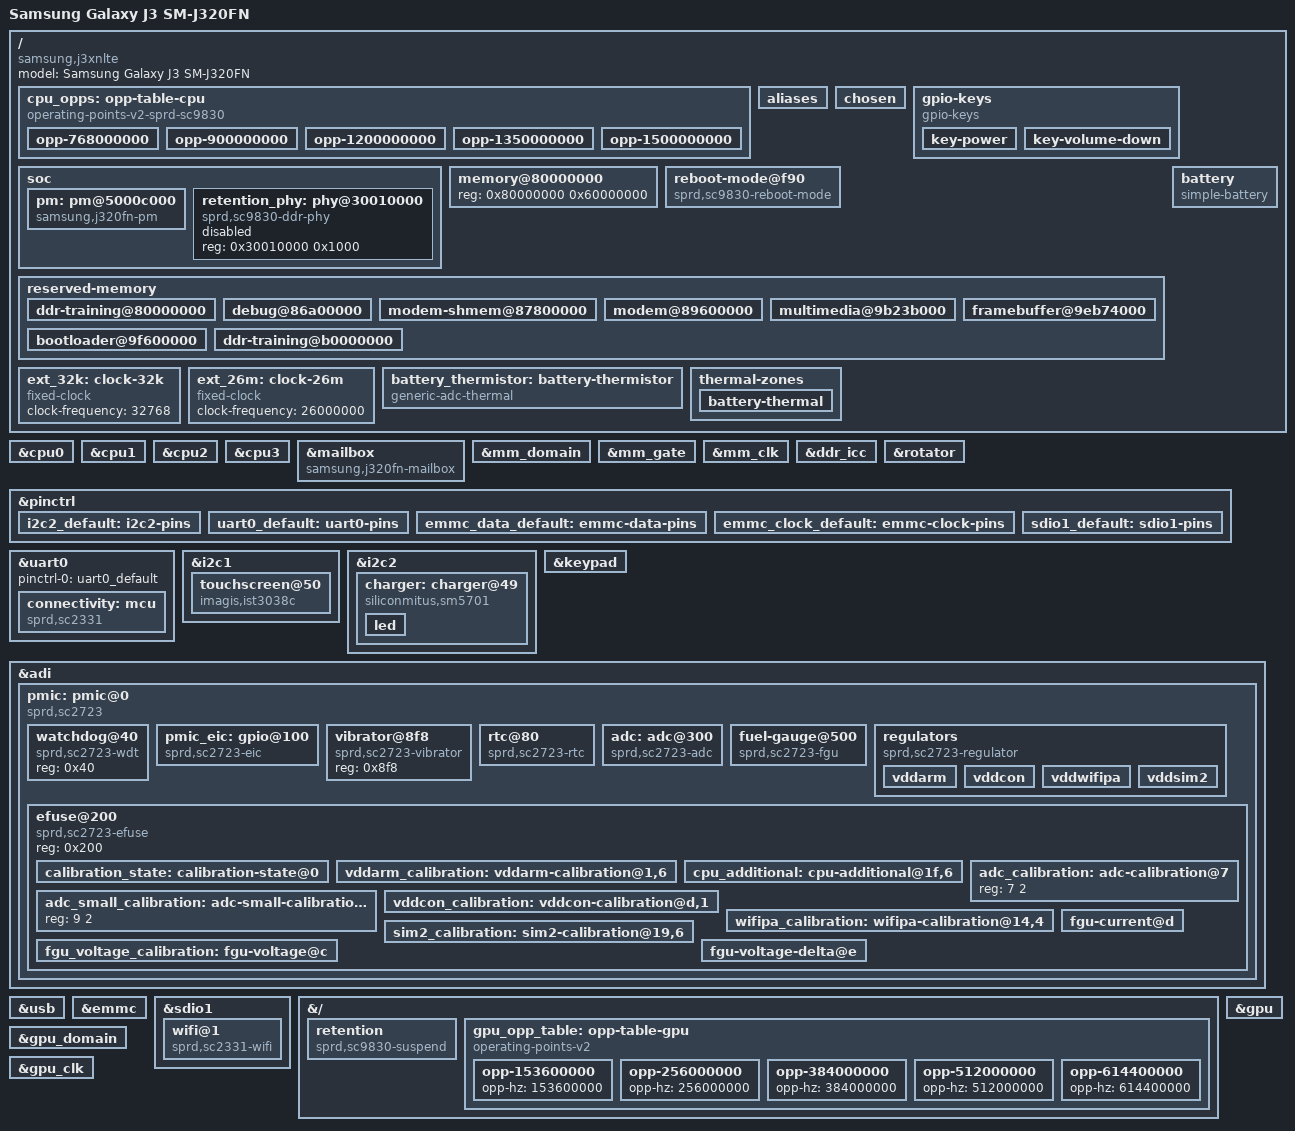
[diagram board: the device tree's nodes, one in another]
// SPDX-License-Identifier: GPL-2.0-only
/dts-v1/;

#include "sc9830.dtsi"
#include <dt-bindings/input/input.h>
#include <dt-bindings/leds/common.h>
#include <dt-bindings/power/sprd,sc9830-reboot-mode.h>

&cpu0 {
	cpu-supply = <&vddarm>;
	operating-points-v2 = <&cpu_opps>;
};

&cpu1 {
	cpu-supply = <&vddarm>;
	operating-points-v2 = <&cpu_opps>;
};

&cpu2 {
	cpu-supply = <&vddarm>;
	operating-points-v2 = <&cpu_opps>;
};

&cpu3 {
	cpu-supply = <&vddarm>;
	operating-points-v2 = <&cpu_opps>;
};

/ {
	model = "Samsung Galaxy J3 SM-J320FN";
	compatible = "samsung,j3xnlte", "sprd,sc9830";

	cpu_opps: opp-table-cpu {
		compatible = "operating-points-v2-sprd-sc9830";
		opp-shared;
		nvmem-cells = <&calibration_state>, <&vddarm_calibration>, <&cpu_additional>;
		nvmem-cell-names = "calibration_state", "vddarm", "additional";

		opp-768000000 {
			opp-hz = /bits/ 64 <768000000>;
			opp-microvolt = <900000>;
			opp-suspend;
		};

		opp-900000000 {
			opp-hz = /bits/ 64 <900000000>;
			opp-microvolt = <900000>;
		};

		opp-1200000000 {
			opp-hz = /bits/ 64 <1200000000>;
			opp-microvolt = <1000000>;
		};

		opp-1350000000 {
			opp-hz = /bits/ 64 <1350000000>;
			opp-microvolt = <1000000>;
		};

		opp-1500000000 {
			opp-hz = /bits/ 64 <1500000000>;
			opp-microvolt = <1100000>;
		};
	};

	aliases {
		serial0 = &uart0;
		i2c1 = &i2c1;
		i2c2 = &i2c2;
		spi0 = &adi;
	};

	chosen {
	};

	gpio-keys {
		compatible = "gpio-keys";

		key-power {
			label = "Power";
			linux,code = <KEY_POWER>;
			gpios = <&pmic_eic 2 GPIO_ACTIVE_LOW>;
			debounce-interval = <5>;
			wakeup-source;
		};

		key-volume-down {
			label = "Volume Down";
			linux,code = <KEY_VOLUMEDOWN>;
			gpios = <&pmic_eic 10 GPIO_ACTIVE_LOW>;
			debounce-interval = <5>;
		};
	};

	soc {
		pm: pm@5000c000 {
			compatible = "samsung,j320fn-pm";
			reg = <0x5000c000 0x1000>;
			mboxes = <&mailbox 1>;
			mbox-names = "pm";
			clocks = <&aon_mux CLK_EMC>;
			clock-names = "emc";
			#clock-cells = <0>;
			status = "disabled";
		};
	};

	memory@80000000 {
		device_type = "memory";
		reg = <0x80000000 0x60000000>;
	};

	reboot-mode@f90 {
		compatible = "sprd,sc9830-reboot-mode";
		reg = <0xf90 0x4>;
		mode-normal = <SC9830_BOOT_NORMAL>;
		mode-recovery = <SC9830_BOOT_RECOVERY>;
		mode-bootloader = <SC9830_BOOT_FASTBOOT>;
	};

	reserved-memory {
		#address-cells = <1>;
		#size-cells = <1>;
		ranges;

		ddr-training@80000000 {
			reg = <0x80000000 0x1000>;
			no-map;
		};

		debug@86a00000 {
			reg = <0x86a00000 0x200000>;
			no-map;
		};

		modem-shmem@87800000 {
			reg = <0x87800000 0x500000>;
			no-map;
		};

		modem@89600000 {
			reg = <0x89600000 0x4380000>;
			no-map;
		};

		multimedia@9b23b000 {
			reg = <0x9b23b000 0x3939000>;
			no-map;
		};

		framebuffer@9eb74000 {
			reg = <0x9eb74000 0xa8c000>;
			no-map;
		};

		bootloader@9f600000 {
			reg = <0x9f600000 0x708000>;
			no-map;
		};

		ddr-training@b0000000 {
			reg = <0xb0000000 0x1000>;
			no-map;
		};
	};


	ext_32k: clock-32k {
		compatible = "fixed-clock";
		#clock-cells = <0>;
		clock-frequency = <32768>;
	};

	ext_26m: clock-26m {
		compatible = "fixed-clock";
		#clock-cells = <0>;
		clock-frequency = <26000000>;
	};

	battery: battery {
		compatible = "simple-battery";
		device-chemistry = "lithium-ion";
		charge-full-design-microamp-hours = <2600000>;
		charge-full-design-temp-table = <25 2600000>, <10 2400000>,
					       <0 2350000>;
		ocv-capacity-celsius = <25>;
		ocv-capacity-table-0 = <4285000 100>, <4247000 95>,
			<4192000 90>, <4139000 85>, <4088000 80>,
			<4044000 75>, <3994000 70>, <3959000 65>,
			<3923000 60>, <3873000 55>, <3838000 50>,
			<3816000 45>, <3799000 40>, <3785000 35>,
			<3775000 30>, <3768000 25>, <3750000 20>,
			<3713000 15>, <3689000 10>, <3673000 5>,
			<3400000 0>;
	};

	battery_thermistor: battery-thermistor {
		compatible = "generic-adc-thermal";
		#thermal-sensor-cells = <0>;
		#io-channel-cells = <0>;
		io-channels = <&adc 1>;
		io-channel-names = "sensor-channel";
		temperature-lookup-table-raw;
		temperature-lookup-table = <
			(-30000) 4210
			(-25000) 4035
			(-20000) 3860
			(-15000) 3729
			(-10000) 3591
			(-7000) 3493
			(-5000) 3431
			(-3000) 3344
			(-2000) 3317
			0 3256
			2000 3152
			3000 3101
			5000 3039
			10000 2828
			15000 2619
			20000 2383
			25000 2145
			30000 1930
			35000 1684
			40000 1502
			45000 1311
			47000 1233
			48000 1197
			50000 1121
			52000 1050
			53000 1020
			55000 969
			58000 899
			60000 850
			65000 733
			70000 659
			75000 589
			80000 521
			85000 450
			90000 390>;
	};

	thermal-zones {
		battery-thermal {
			polling-delay = <1000>;
			polling-delay-passive = <0>;
			thermal-sensors = <&battery_thermistor>;
		};
	};

};

&mailbox {
	compatible = "samsung,j320fn-mailbox";
	reg = <0x400a0000 0x100>, <0x400a8000 0x100>,
	      <0x5000c800 0x10>, <0x400a8100 0x100>;
	status = "okay";
};

&pm {
	status = "okay";
};

&mm_domain {
	status = "okay";
};

&mm_gate {
	status = "okay";
};

&mm_clk {
	status = "okay";
};

&ddr_icc {
	status = "okay";
};

&rotator {
	status = "okay";
};

&pinctrl {


	i2c2_default: i2c2-pins {
		function = "i2c2";
		groups = "i2c2";
	};

	uart0_default: uart0-pins {
		function = "uart0";
		groups = "uart0";
	};

	emmc_data_default: emmc-data-pins {
		function = "emmc";
		groups = "emmc-data";
		sprd,drive-level = <1>;
		bias-pull-up;
	};

	emmc_clock_default: emmc-clock-pins {
		function = "emmc";
		groups = "emmc-clock";
		sprd,drive-level = <2>;
		bias-disable;
	};

	sdio1_default: sdio1-pins {
		function = "sdio1";
		groups = "sdio1";
	};
};

&uart0 {
	status = "okay";
	pinctrl-names = "default";
	pinctrl-0 = <&uart0_default>;

	connectivity: mcu {
		compatible = "sprd,sc2331";
		vddcon-supply = <&vddcon>;
		vddwifipa-supply = <&vddwifipa>;
		clocks = <&aon_gate CLK_AUX0>;
		clock-names = "ext_clock";
		reset-gpios = <&gpio 130 GPIO_ACTIVE_LOW>;
		host-wake-gpios = <&gpio 97 GPIO_ACTIVE_HIGH>;
		device-wake-gpios = <&gpio 133 GPIO_ACTIVE_HIGH>;
	};
};

&i2c1 {
	status = "okay";
	clock-frequency = <100000>;
	assigned-clocks = <&ap_clk CLK_I2C1>;
	assigned-clock-rates = <26000000>;

	touchscreen@50 {
		compatible = "imagis,ist3038c";
		reg = <0x50>;
		interrupt-parent = <&gpio>;
		interrupts = <142 IRQ_TYPE_EDGE_FALLING>;
		vdd-supply = <&vddsim2>;
		touchscreen-size-x = <720>;
		touchscreen-size-y = <1280>;
		linux,keycodes = <KEY_APPSELECT KEY_BACK>;
	};
};

&i2c2 {
	status = "okay";
	assigned-clocks = <&ap_clk CLK_I2C2>;
	assigned-clock-parents = <&ext_26m>;
	assigned-clock-rates = <26000000>;
	clock-frequency = <100000>;
	pinctrl-names = "default";
	pinctrl-0 = <&i2c2_default>;

	charger: charger@49 {
		compatible = "siliconmitus,sm5701";
		reg = <0x49>;
		interrupt-parent = <&gpio>;
		interrupts = <92 IRQ_TYPE_EDGE_FALLING>;

		led {
			function = LED_FUNCTION_FLASH;
			color = <LED_COLOR_ID_WHITE>;
			led-max-microamp = <100000>;
		};
	};
};

&keypad {
	status = "okay";
	keypad,num-rows = <2>;
	keypad,num-columns = <3>;
	linux,keymap = <MATRIX_KEY(0, 0, KEY_VOLUMEUP)
			MATRIX_KEY(0, 1, KEY_VOLUMEUP)
			MATRIX_KEY(0, 2, KEY_HOMEPAGE)>;
	wakeup-source;
};

&adi {
	status = "okay";

	pmic: pmic@0 {
		compatible = "sprd,sc2723";
		reg = <0>;
		spi-max-frequency = <26000000>;
		interrupts = <GIC_SPI 38 IRQ_TYPE_LEVEL_HIGH>;
		interrupt-controller;
		#interrupt-cells = <1>;
		#address-cells = <1>;
		#size-cells = <0>;

		watchdog@40 {
			compatible = "sprd,sc2723-wdt";
			reg = <0x40>;
		};

		pmic_eic: gpio@100 {
			compatible = "sprd,sc2723-eic";
			reg = <0x100>;
			interrupts = <5>;
			gpio-controller;
			#gpio-cells = <2>;
			interrupt-controller;
			#interrupt-cells = <2>;
		};

		vibrator@8f8 {
			compatible = "sprd,sc2723-vibrator";
			reg = <0x8f8>;
		};

		rtc@80 {
			compatible = "sprd,sc2723-rtc";
			reg = <0x80>;
			interrupts = <2>;
			start-year = <2015>;
		};

		adc: adc@300 {
			compatible = "sprd,sc2723-adc";
			reg = <0x300>;
			interrupts = <0>;
			#io-channel-cells = <1>;
			hwlocks = <&hwlock 4>;
			clocks = <&aon_gate CLK_SINDRV>;
			clock-names = "reference";
			nvmem-cells = <&calibration_state>,
				      <&adc_calibration>, <&adc_small_calibration>;
			nvmem-cell-names = "calibration_state",
					   "big_scale_calib", "small_scale_calib";
		};

		fuel-gauge@500 {
			monitored-battery = <&battery>;
			power-supplies = <&charger>;
			io-channels = <&battery_thermistor>, <&adc 5>;
			io-channel-names = "bat-temp", "bat-voltage";
			compatible = "sprd,sc2723-fgu";
			reg = <0x500>;
			interrupts = <4>;
			nvmem-cells = <&calibration_state>,
				      <&fgu_voltage_calibration>;
			nvmem-cell-names = "calibration_state", "fgu_calib";
			sprd,calib-resistance-micro-ohms = <19900>;
		};

		regulators {
			compatible = "sprd,sc2723-regulator";
			nvmem-cells = <&calibration_state>, <&vddcon_calibration>,
				      <&wifipa_calibration>, <&sim2_calibration>;
			nvmem-cell-names = "calibration_state", "vddcon",
					   "vddwifipa", "vddsim2";

			vddarm: vddarm {
				regulator-name = "vddarm";
				regulator-min-microvolt = <600000>;
				regulator-max-microvolt = <3125000>;
				regulator-always-on;
				regulator-boot-on;
			};

			vddcon: vddcon {
				regulator-name = "vddcon";
				regulator-min-microvolt = <1600000>;
				regulator-max-microvolt = <1600000>;
			};

			vddwifipa: vddwifipa {
				regulator-name = "vddwifipa";
				regulator-min-microvolt = <3300000>;
				regulator-max-microvolt = <3300000>;
			};

			vddsim2: vddsim2 {
				regulator-name = "vddsim2";
				regulator-min-microvolt = <3000000>;
				regulator-max-microvolt = <3000000>;
			};
		};

		efuse@200 {
			compatible = "sprd,sc2723-efuse";
			reg = <0x200>;
			#address-cells = <1>;
			#size-cells = <1>;

			calibration_state: calibration-state@0 {
				reg = <0 1>;
				bits = <7 1>;
			};

			vddarm_calibration: vddarm-calibration@1,6 {
				reg = <1 2>;
				bits = <6 7>;
			};

			cpu_additional: cpu-additional@1f,6 {
				reg = <31 1>;
				bits = <6 2>;
			};

			adc_calibration: adc-calibration@7 {
				reg = <7 2>;
			};

			adc_small_calibration: adc-small-calibration@9 {
				reg = <9 2>;
				};

			vddcon_calibration: vddcon-calibration@d,1 {
				reg = <13 1>;
				bits = <1 7>;
			};

			wifipa_calibration: wifipa-calibration@14,4 {
				reg = <20 2>;
				bits = <4 6>;
			};

			sim2_calibration: sim2-calibration@19,6 {
				reg = <25 2>;
				bits = <6 6>;
			};

			fgu_voltage_calibration: fgu-voltage@c {
				reg = <12 2>;
				bits = <0 9>;
			};

			fgu-current@d {
				reg = <13 2>;
				bits = <1 9>;
			};

			fgu-voltage-delta@e {
				reg = <14 1>;
				bits = <2 6>;
			};
		};
	};
};

&usb {
	status = "okay";
	dr_mode = "peripheral";
	maximum-speed = "full-speed";
	phy_type = "utmi";


};

&emmc {
	status = "okay";
	assigned-clocks = <&ap_clk CLK_EMMC>;
	assigned-clock-parents = <&aon_gate CLK_TWPLL_384M>;
	pinctrl-names = "default";
	pinctrl-0 = <&emmc_clock_default>, <&emmc_data_default>;
	bus-width = <1>;
	max-frequency = <12000000>;
	non-removable;
	no-sd;
	no-sdio;


};

&sdio1 {
	status = "okay";
	assigned-clocks = <&ap_clk CLK_SDIO1>;
	assigned-clock-rates = <96000000>;
	bus-width = <4>;
	max-frequency = <48000000>;
	sprd,phy-delay = <3 3 3>;
	pinctrl-names = "default";
	pinctrl-0 = <&sdio1_default>;
	non-removable;
	no-sd;
	no-mmc;
	no-1-8-v;
	mmc-pwrseq = <&connectivity>;

	wifi@1 {
		compatible = "sprd,sc2331-wifi";
		reg = <1>;
		sprd,boot-controller = <&connectivity>;
	};
};

&{/soc} {
	retention_phy: phy@30010000 {
		compatible = "sprd,sc9830-ddr-phy", "syscon";
		reg = <0x30010000 0x1000>;
		status = "disabled";
	};

};

&{/} {
	retention {
		compatible = "sprd,sc9830-suspend";
		sprd,ap-clk = <&ap_clk>;
		sprd,ap-ahb = <&apahb>;
		sprd,ap-apb = <&apapb>;
		sprd,aon = <&aon_gate>;
		sprd,pub = <&ddr_pmu>;
		sprd,pmu = <&pmu>;
		sprd,dmc = <&ddr_icc>;
		sprd,phy = <&retention_phy>;
		sprd,pmic = <&pmic>;
	};
};

&gpu_domain {
	status = "okay";
};

&gpu_clk {
	status = "okay";
};

&gpu {
	status = "okay";
	assigned-clocks = <&gpu_clk>;
	assigned-clock-rates = <256000000>;
	operating-points-v2 = <&gpu_opp_table>;
};

&{/} {
	gpu_opp_table: opp-table-gpu {
		compatible = "operating-points-v2";

		opp-153600000 {
			opp-hz = /bits/ 64 <153600000>;
		};

		opp-256000000 {
			opp-hz = /bits/ 64 <256000000>;
		};

		opp-384000000 {
			opp-hz = /bits/ 64 <384000000>;
		};

		opp-512000000 {
			opp-hz = /bits/ 64 <512000000>;
		};

		opp-614400000 {
			opp-hz = /bits/ 64 <614400000>;
		};
	};
};
